# STM32C531 register map
File version: 0.1
CPU: CM33 r0p4, little endian, MPU, FPU, 4 interrupt priority bits
Registers are 32-bit, read-write, reset 0x0 unless marked. A register's access mark holds for its fields unless they carry their own. Offsets are from the block's base; [hi:lo] are bit positions; {n}, {i} and the like mark numbered series; 'fields as' and 'values as' point back to an identical list.

## GPIOA — GPIO address block description
Base 0x42020000
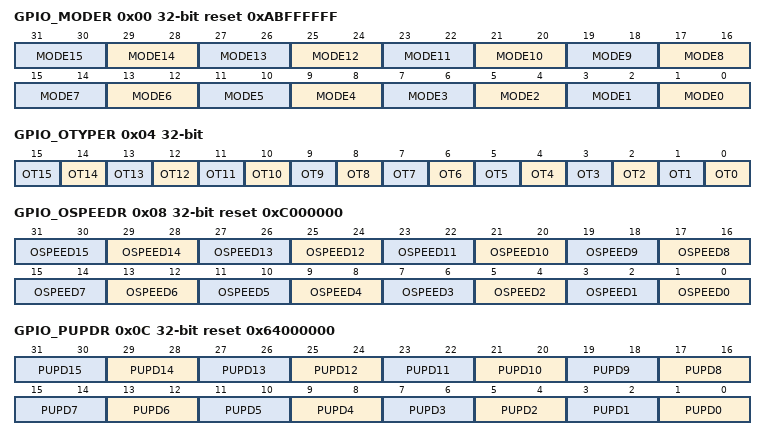
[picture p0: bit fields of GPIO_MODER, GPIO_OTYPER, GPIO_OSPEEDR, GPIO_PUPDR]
0x00 GPIO_MODER reset 0xABFFFFFF — GPIO port mode register
  [all] fields
    0=Input mode; 1=General purpose output mode; 2=Alternate function mode; 3=Analog mode (reset state)
  [2n+1:2n] MODE{n} (n=0..15) — Port x configuration I/O pin y
0x04 GPIO_OTYPER — GPIO port output type register
  [all] fields
    0=Output push-pull (reset state); 1=Output open-drain
  [n] OT{n} (n=0..15) — Port x configuration I/O pin y
0x08 GPIO_OSPEEDR reset 0xC000000 — GPIO port output speed register
  [all] fields
    0=Low speed; 1=Medium speed; 2=High speed; 3=Very-high speed
  [2n+1:2n] OSPEED{n} (n=0..15) — Port x configuration I/O pin y
0x0C GPIO_PUPDR reset 0x64000000 — GPIO port pull-up/pull-down register
  [all] fields
    0=No pull-up, pull-down; 1=Pull-up; 2=Pull-down
  [2n+1:2n] PUPD{n} (n=0..15) — Port x configuration I/O pin y
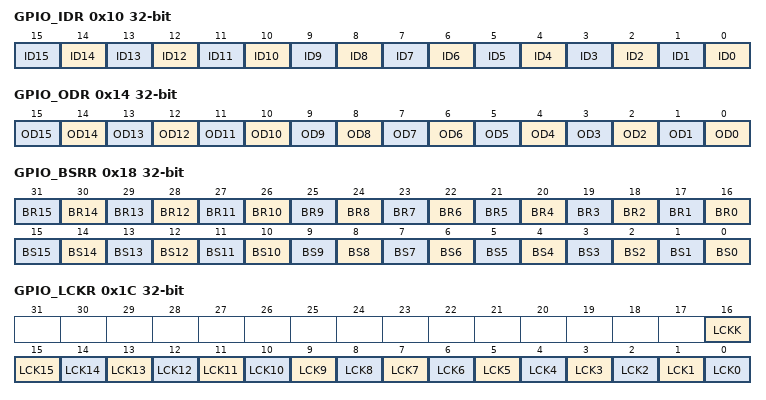
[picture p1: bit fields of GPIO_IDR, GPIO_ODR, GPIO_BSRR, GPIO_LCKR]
0x10 GPIO_IDR ro (reset mask 0xFFFF0000) — GPIO port input data register
  [n] ID{n} (n=0..15) — Port x input data I/O pin y
0x14 GPIO_ODR — GPIO port output data register
  [n] OD{n} (n=0..15) — Port output data I/O pin y
0x18 GPIO_BSRR wo — GPIO port bit set/reset register
  [n+16] BR{n} (n=0..15) — Port x reset I/O pin y
    0=No action on the corresponding ODy bit; 1=Resets the corresponding ODy bit
  [n] BS{n} (n=0..15) — Port x set I/O pin y
    0=No action on the corresponding ODy bit; 1=Sets the corresponding ODy bit
0x1C GPIO_LCKR — GPIO port configuration lock register
  [16] LCKK — Lock key
    0=Port configuration lock key not active; 1=Port configuration lock key active
  [n] LCK{n} (n=0..15) — Port x lock I/O pin y
    0=Port configuration not locked; 1=Port configuration locked
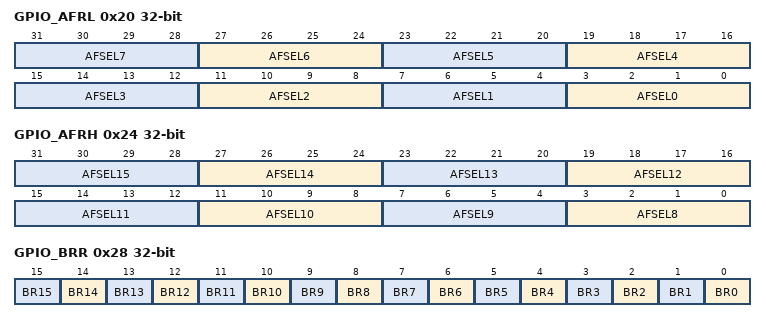
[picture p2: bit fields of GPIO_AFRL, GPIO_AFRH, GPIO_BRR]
0x20 GPIO_AFRL — GPIO alternate function low register
  [all] fields
    {v}=AF{v} (v=0..15)
  [4n+3:4n] AFSEL{n} (n=0..7) — Alternate function selection for port x I/O pin y
0x24 GPIO_AFRH — GPIO alternate function high register
  [all] fields
    {v}=AF{v} (v=0..15)
  [4n-29:4n-32] AFSEL{n} (n=8..15) — Alternate function selection for port x I/O pin y
0x28 GPIO_BRR wo — GPIO port bit reset register
  [all] fields
    0=No action on the corresponding ODy bit; 1=Reset the corresponding ODy bit
  [n] BR{n} (n=0..15) — Port x reset IO pin y

## GPIOB — GPIO address block description
Base 0x42020400
Registers as GPIOA; these are added or differ:
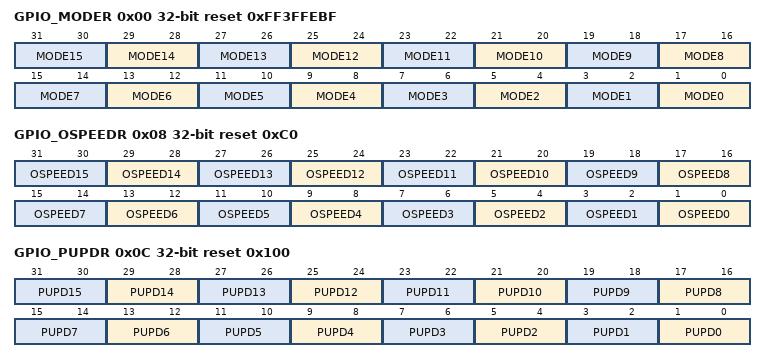
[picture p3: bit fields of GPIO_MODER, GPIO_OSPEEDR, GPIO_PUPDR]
0x00 GPIO_MODER reset 0xFF3FFEBF — GPIO port mode register
  [all] fields
    0=Input mode; 1=General purpose output mode; 2=Alternate function mode; 3=Analog mode (reset state)
  [2n+1:2n] MODE{n} (n=0..15) — Port x configuration I/O pin y
0x08 GPIO_OSPEEDR reset 0xC0 — GPIO port output speed register
  [all] fields
    0=Low speed; 1=Medium speed; 2=High speed; 3=Very-high speed
  [2n+1:2n] OSPEED{n} (n=0..15) — Port x configuration I/O pin y
0x0C GPIO_PUPDR reset 0x100 — GPIO port pull-up/pull-down register
  [all] fields
    0=No pull-up, pull-down; 1=Pull-up; 2=Pull-down
  [2n+1:2n] PUPD{n} (n=0..15) — Port x configuration I/O pin y

## GPIOC — GPIO address block description
Base 0x42020800
Same registers: GPIOD 0x42020C00, GPIOE 0x42021000, GPIOH 0x42021C00
Registers as GPIOA; these are added or differ:
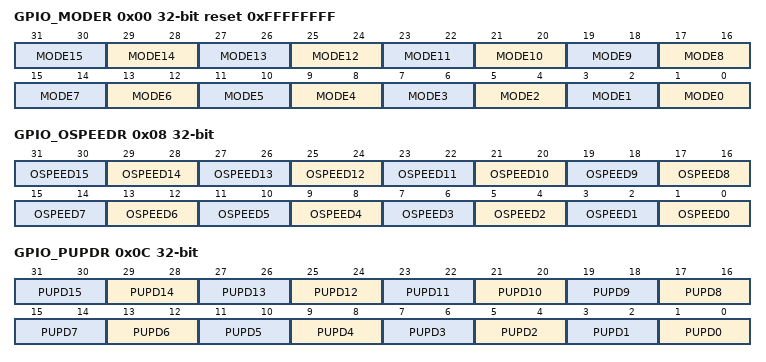
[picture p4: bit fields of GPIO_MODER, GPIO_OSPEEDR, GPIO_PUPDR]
0x00 GPIO_MODER reset 0xFFFFFFFF — GPIO port mode register
  [all] fields
    0=Input mode; 1=General purpose output mode; 2=Alternate function mode; 3=Analog mode (reset state)
  [2n+1:2n] MODE{n} (n=0..15) — Port x configuration I/O pin y
0x08 GPIO_OSPEEDR — GPIO port output speed register
  [all] fields
    0=Low speed; 1=Medium speed; 2=High speed; 3=Very-high speed
  [2n+1:2n] OSPEED{n} (n=0..15) — Port x configuration I/O pin y
0x0C GPIO_PUPDR — GPIO port pull-up/pull-down register
  [all] fields
    0=No pull-up, pull-down; 1=Pull-up; 2=Pull-down
  [2n+1:2n] PUPD{n} (n=0..15) — Port x configuration I/O pin y

## RAMCFG — RAMCFG register block
Base 0x40026000
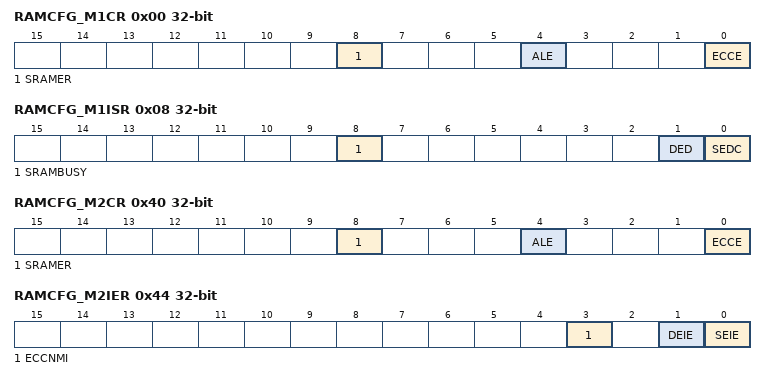
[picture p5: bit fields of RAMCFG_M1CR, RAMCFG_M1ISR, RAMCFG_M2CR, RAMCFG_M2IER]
0x00 RAMCFG_M1CR (reset mask 0xFFFFFFF0) — RAMCFG memory 1 control register
  [8] SRAMER — SRAM erase
    0=No erase operation ongoing; 1=Erase operation ongoing
  [4] ALE — Address latch enable
    0=Failing address not stored in the SRAMx ECC single/double error address registers; 1=Failing address stored in the SRAMx ECC single/double error address registers
  [0] ECCE — ECC enable.
    0=ECC disabled; 1=ECC enabled
0x08 RAMCFG_M1ISR ro — RAMCFG memory 1 interrupt status register
  [8] SRAMBUSY — SRAM busy with erase operation
    0=No erase operation ongoing; 1=Erase operation ongoing
  [1] DED — ECC double error detected
    0=No double error; 1=Double error detected
  [0] SEDC — ECC single error detected and corrected
    0=No single error; 1=Single error detected and corrected
0x28 RAMCFG_M1ERKEYR wo — RAMCFG memory 1 erase key register
  [7:0] ERASEKEY — Erase write protection key
0x40 RAMCFG_M2CR (reset mask 0xFFFFFFF0) — RAMCFG memory 2 control register
  fields as RAMCFG_M1CR
0x44 RAMCFG_M2IER — RAMCFG memory 2 interrupt enable register
  [3] ECCNMI — Double error NMI
    0=NMI not generated in case of ECC double error; 1=NMI generated in case of ECC double error
  [1] DEIE — ECC double error interrupt enable
    0=Double error interrupt disabled; 1=Double error interrupt enabled
  [0] SEIE — ECC single error interrupt enable
    0=Single error interrupt disabled; 1=Single error interrupt enabled
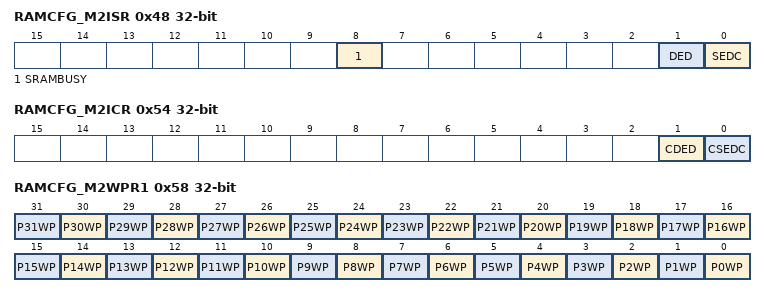
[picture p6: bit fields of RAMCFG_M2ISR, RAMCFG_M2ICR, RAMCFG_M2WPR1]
0x48 RAMCFG_M2ISR ro — RAMCFG memory 2 interrupt status register
  fields as RAMCFG_M1ISR
0x4C RAMCFG_M2SEAR ro — RAMCFG memory 2 ECC single error address register
  [31:0] ESEA — ECC single error address
0x50 RAMCFG_M2DEAR ro — RAMCFG memory 2 ECC double error address register
  [31:0] EDEA — ECC double error address
0x54 RAMCFG_M2ICR — RAMCFG memory 2 interrupt clear register
  [1] CDED — Clear ECC double error detected
  [0] CSEDC — Clear ECC single error detected and corrected
0x58 RAMCFG_M2WPR1 — RAMCFG memory 2 write protection register 1
  [all] fields
    0=Write protection of SRAM2 1-Kbyte page y is disabled; 1=Write protection of SRAM2 1-Kbyte page y is enabled
  [n] P{n}WP (n=0..31) — SRAM2 1-Kbyte page y write protection
0x64 RAMCFG_M2ECCKEYR wo — RAMCFG memory 2ECC key register
  [7:0] ECCKEY — ECC write protection key
0x68 RAMCFG_M2ERKEYR wo — RAMCFG memory 2 erase key register
  [7:0] ERASEKEY — Erase write protection key
